AUTOSAR XML (schema 00048)
package /myproject/Application/Executable
  executable IAMApp01Exe: category=APPLICATION_LEVEL, reporting-behavior=REPORTS-EXECUTION-STATE
    root sw component prototype RootSwComponent: application-type=IAMApp01
package /myproject/Application/Process
  process IAMApp01_process: design=IAMApp01_processDesign, executable=IAMApp01Exe, state-dependent-startup-config{function-group-state=MachineState.Driving, startup-config=startup_config}
package /myproject/Application/ProcessDesign
  process design IAMApp01_processDesign: executable=IAMApp01Exe
package /myproject/Application/SwComponent
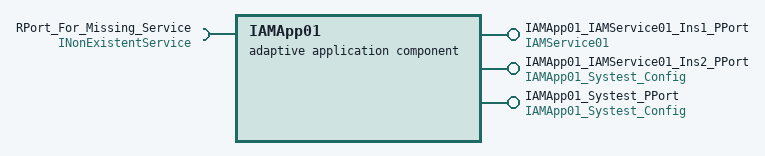
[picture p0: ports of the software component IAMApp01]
  adaptive application sw component type IAMApp01
    provide port IAMApp01_IAMService01_Ins1_PPort: provided-interface=IAMService01
    provide port IAMApp01_IAMService01_Ins2_PPort: provided-interface=IAMApp01_Systest_Config
    provide port IAMApp01_Systest_PPort: provided-interface=IAMApp01_Systest_Config
    require port RPort_For_Missing_Service: required-interface=INonExistentService
package /myproject/Service/IAMService01
  someip service instance to machine mapping IAMApp01_IAMService01_Ins1_ProvidedServiceInstance_toMachine: communication-connector=ECU1CommunicationConnector, service-instance=IAMApp01_IAMService01_Ins1_Provided_Instance, udp-port=1
  service instance to port prototype mapping IAMApp01_IAMService01_Ins1_ProvidedServiceInstance_toPort: port-prototype=IAMApp01_IAMService01_Ins1_PPort, process=IAMApp01_processDesign, service-instance=IAMApp01_IAMService01_Ins1_Provided_Instance
  provided someip service instance IAMApp01_IAMService01_Ins1_Provided_Instance: service-interface-deployment=IAMService01_Dep, service-instance-id=1
  someip service instance to machine mapping IAMApp01_IAMService01_Ins2_ProvidedServiceInstance_toMachine: communication-connector=ECU1CommunicationConnector, service-instance=IAMApp01_IAMService01_Ins2_Provided_Instance, udp-port=2
  service instance to port prototype mapping IAMApp01_IAMService01_Ins2_ProvidedServiceInstance_toPort_BROKEN: port-prototype=IDoNotExist_PPort, process=IAMApp01_processDesign, service-instance=IAMApp01_IAMService01_Ins2_Provided_Instance
  provided someip service instance IAMApp01_IAMService01_Ins2_Provided_Instance: service-interface-deployment=IAMService01_Dep, service-instance-id=2
package /myproject/Service/Systest
  someip service instance to machine mapping IAMApp01_Systest_ProvidedServiceInstance_toMachine: communication-connector=ECU1CommunicationConnector, service-instance=IAMApp01_Systest_Provided_Instance, udp-port=31401
  service instance to port prototype mapping IAMApp01_Systest_ProvidedServiceInstance_toPort: port-prototype=IAMApp01_Systest_PPort, process=IAMApp01_processDesign, service-instance=IAMApp01_Systest_Provided_Instance
  provided someip service instance IAMApp01_Systest_Provided_Instance: service-interface-deployment=IAMApp01_Systest_Config_Dep, service-instance-id=1
package /myproject/Service/Someip/Deployment
  someip service interface deployment IAMService01_Dep: service-interface=IAMService01, service-interface-id=1, service-interface-version=major-version=1
  someip service interface deployment IAMApp01_Systest_Config_Dep: service-interface=IAMApp01_Systest_Config, service-interface-id=99, service-interface-version=major-version=1
package /myproject/System/ProcessToMachineMappingSet
  process to machine mapping set IAMApp01procToMachineMappingSet
    process to machine mapping procToMachineMapping_BROKEN: machine=ECU2Machine_Not_Defined, process=DoesNotExist_process
package /myproject/System/StartupConfigSet
  startup config set IAMApp01_startup_set
    startup config startup_config: scheduling-policy=SCHEDULING-POLICY-ROUND-ROBIN, scheduling-priority=12
package /myproject/test
  service interface IAMService01: major-version=1
  service interface IAMApp01_Systest_Config: major-version=1
package /Machine
  machine ECU1Machine: machine-design=ECU1MachineDesign
    function-groups:
      mode declaration group prototype MachineState: type=ECU1Machine_MachineState_ModeDeclarationGroup
  machine design ECU1MachineDesign
    ethernet communication connector ECU1CommunicationConnector: unicast-network-endpoint=ECU1NetworkEndpoint
  mode declaration group ECU1Machine_MachineState_ModeDeclarationGroup
    mode Driving
  ethernet cluster EthCluster
    ethernet physical channel EthPhysChannel1
      network endpoint ECU1NetworkEndpoint: network-endpoint-addresses=ipv-4-configuration=ipv-4-address=192.168.100.5
